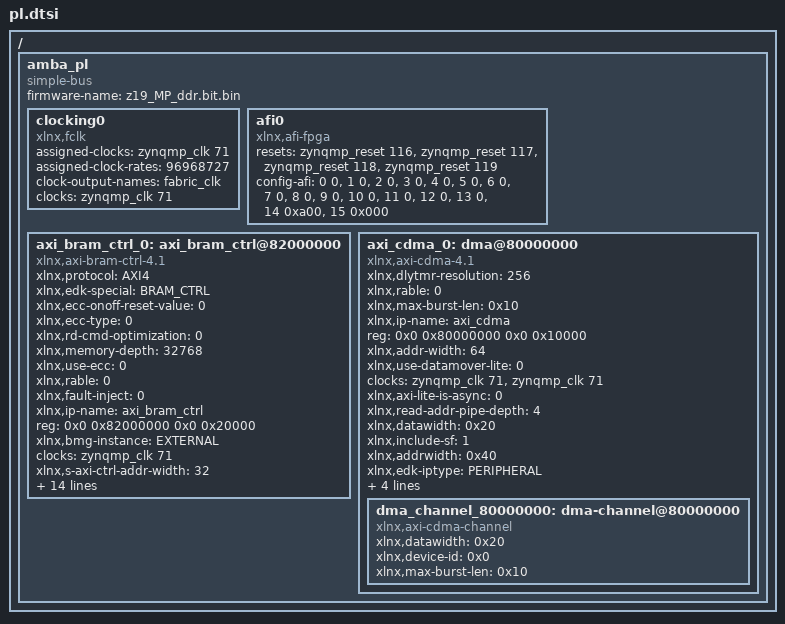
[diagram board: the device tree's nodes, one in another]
/ {
	amba_pl: amba_pl {
		ranges;
		compatible = "simple-bus";
		#address-cells = <2>;
		#size-cells = <2>;
		firmware-name = "z19_MP_ddr.bit.bin";
		clocking0: clocking0 {
			compatible = "xlnx,fclk";
			status = "okay";
			assigned-clocks = <&zynqmp_clk 71>;
			assigned-clock-rates = <96968727>;
			#clock-cells = <0>;
			clock-output-names = "fabric_clk";
			clocks = <&zynqmp_clk 71>;
		};
		afi0: afi0 {
			status = "okay";
			compatible = "xlnx,afi-fpga";
			resets = <&zynqmp_reset 116>, <&zynqmp_reset 117>, <&zynqmp_reset 118>, <&zynqmp_reset 119>;
			config-afi = < 0 0>, <1 0>, <2 0>, <3 0>, <4 0>, <5 0>, <6 0>, <7 0>, <8 0>, <9 0>, <10 0>, <11 0>, <12 0>, <13 0>, <14 0xa00>, <15 0x000>;
		};
		axi_bram_ctrl_0: axi_bram_ctrl@82000000 {
			xlnx,protocol = "AXI4";
			xlnx,edk-special = "BRAM_CTRL";
			compatible = "xlnx,axi-bram-ctrl-4.1";
			xlnx,ecc-onoff-reset-value = <0>;
			xlnx,ecc-type = <0>;
			xlnx,rd-cmd-optimization = <0>;
			xlnx,memory-depth = <32768>;
			xlnx,use-ecc = <0>;
			xlnx,rable = <0>;
			xlnx,fault-inject = <0>;
			xlnx,ip-name = "axi_bram_ctrl";
			reg = <0x0 0x82000000 0x0 0x20000>;
			xlnx,bmg-instance = "EXTERNAL";
			clocks = <&zynqmp_clk 71>;
			xlnx,s-axi-ctrl-addr-width = <32>;
			xlnx,read-latency = <1>;
			xlnx,id-width = <0>;
			xlnx,s-axi-supports-narrow-burst = <0>;
			xlnx,supports-narrow-burst = <0>;
			xlnx,single-port-bram = <0>;
			xlnx,ecc = <0>;
			xlnx,edk-iptype = "PERIPHERAL";
			status = "okay";
			clock-names = "s_axi_aclk";
			xlnx,data-width = <32>;
			xlnx,bram-addr-width = <15>;
			xlnx,bram-inst-mode = "EXTERNAL";
			xlnx,s-axi-ctrl-data-width = <32>;
			xlnx,mem-depth = <32768>;
			xlnx,s-axi-id-width = <1>;
			xlnx,name = "axi_bram_ctrl_0";
		};
		axi_cdma_0: dma@80000000 {
			compatible = "xlnx,axi-cdma-4.1" , "xlnx,axi-cdma-1.00.a";
			xlnx,dlytmr-resolution = <256>;
			xlnx,rable = <0>;
			#dma-cells = <1>;
			xlnx,max-burst-len = <0x10>;
			xlnx,ip-name = "axi_cdma";
			reg = <0x0 0x80000000 0x0 0x10000>;
			xlnx,addr-width = <64>;
			xlnx,use-datamover-lite = <0>;
			clocks = <&zynqmp_clk 71>, <&zynqmp_clk 71>;
			xlnx,axi-lite-is-async = <0>;
			xlnx,read-addr-pipe-depth = <4>;
			xlnx,datawidth = <0x20>;
			xlnx,include-sf = <1>;
			xlnx,addrwidth = <0x40>;
			xlnx,edk-iptype = "PERIPHERAL";
			xlnx,include-dre = <0x0>;
			status = "okay";
			clock-names = "m_axi_aclk" , "s_axi_lite_aclk";
			xlnx,lite-mode = <0x0>;
			xlnx,write-addr-pipe-depth = <4>;
			xlnx,name = "axi_cdma_0";
			dma_channel_80000000: dma-channel@80000000 {
				xlnx,datawidth = <0x20>;
				xlnx,device-id = <0x0>;
				compatible = "xlnx,axi-cdma-channel";
				xlnx,max-burst-len = <0x10>;
			};
		};
	};
};
